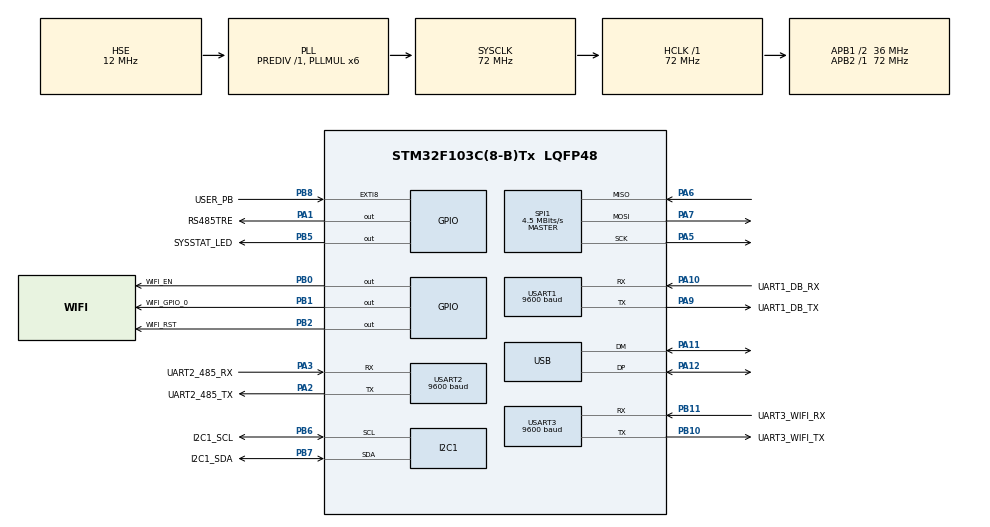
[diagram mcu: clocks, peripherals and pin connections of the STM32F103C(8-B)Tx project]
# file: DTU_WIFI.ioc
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Dma.Request0=USART1_TX
Dma.Request1=USART1_RX
Dma.Request2=USART2_TX
Dma.Request3=USART2_RX
Dma.Request4=USART3_TX
Dma.Request5=USART3_RX
Dma.USART1_RX.1.Direction=DMA_PERIPH_TO_MEMORY
Dma.USART1_RX.1.Instance=DMA1_Channel5
Dma.USART1_RX.1.MemDataAlignment=DMA_MDATAALIGN_BYTE
Dma.USART1_RX.1.MemInc=DMA_MINC_ENABLE
Dma.USART1_RX.1.Mode=DMA_CIRCULAR
Dma.USART1_RX.1.PeriphDataAlignment=DMA_PDATAALIGN_BYTE
Dma.USART1_RX.1.PeriphInc=DMA_PINC_DISABLE
Dma.USART1_RX.1.Priority=DMA_PRIORITY_LOW
Dma.USART1_TX.0.Direction=DMA_MEMORY_TO_PERIPH
Dma.USART1_TX.0.Instance=DMA1_Channel4
Dma.USART1_TX.0.MemDataAlignment=DMA_MDATAALIGN_BYTE
Dma.USART1_TX.0.MemInc=DMA_MINC_ENABLE
Dma.USART1_TX.0.Mode=DMA_CIRCULAR
Dma.USART1_TX.0.PeriphDataAlignment=DMA_PDATAALIGN_BYTE
Dma.USART1_TX.0.PeriphInc=DMA_PINC_DISABLE
Dma.USART1_TX.0.Priority=DMA_PRIORITY_LOW
Dma.USART2_RX.3.Direction=DMA_PERIPH_TO_MEMORY
Dma.USART2_RX.3.Instance=DMA1_Channel6
Dma.USART2_RX.3.MemDataAlignment=DMA_MDATAALIGN_BYTE
Dma.USART2_RX.3.MemInc=DMA_MINC_ENABLE
Dma.USART2_RX.3.Mode=DMA_CIRCULAR
Dma.USART2_RX.3.PeriphDataAlignment=DMA_PDATAALIGN_BYTE
Dma.USART2_RX.3.PeriphInc=DMA_PINC_DISABLE
Dma.USART2_RX.3.Priority=DMA_PRIORITY_LOW
Dma.USART2_TX.2.Direction=DMA_MEMORY_TO_PERIPH
Dma.USART2_TX.2.Instance=DMA1_Channel7
Dma.USART2_TX.2.MemDataAlignment=DMA_MDATAALIGN_BYTE
Dma.USART2_TX.2.MemInc=DMA_MINC_ENABLE
Dma.USART2_TX.2.Mode=DMA_CIRCULAR
Dma.USART2_TX.2.PeriphDataAlignment=DMA_PDATAALIGN_BYTE
Dma.USART2_TX.2.PeriphInc=DMA_PINC_DISABLE
Dma.USART2_TX.2.Priority=DMA_PRIORITY_LOW
Dma.USART3_RX.5.Direction=DMA_PERIPH_TO_MEMORY
Dma.USART3_RX.5.Instance=DMA1_Channel3
Dma.USART3_RX.5.MemDataAlignment=DMA_MDATAALIGN_BYTE
Dma.USART3_RX.5.MemInc=DMA_MINC_ENABLE
Dma.USART3_RX.5.Mode=DMA_CIRCULAR
Dma.USART3_RX.5.PeriphDataAlignment=DMA_PDATAALIGN_BYTE
Dma.USART3_RX.5.PeriphInc=DMA_PINC_DISABLE
Dma.USART3_RX.5.Priority=DMA_PRIORITY_LOW
Dma.USART3_TX.4.Direction=DMA_MEMORY_TO_PERIPH
Dma.USART3_TX.4.Instance=DMA1_Channel2
Dma.USART3_TX.4.MemDataAlignment=DMA_MDATAALIGN_BYTE
Dma.USART3_TX.4.MemInc=DMA_MINC_ENABLE
Dma.USART3_TX.4.Mode=DMA_CIRCULAR
Dma.USART3_TX.4.PeriphDataAlignment=DMA_PDATAALIGN_BYTE
Dma.USART3_TX.4.PeriphInc=DMA_PINC_DISABLE
Dma.USART3_TX.4.Priority=DMA_PRIORITY_LOW
IWDG.Prescaler=IWDG_PRESCALER_64
Mcu.Family=STM32F1
Mcu.Name=STM32F103C(8-B)Tx
Mcu.Package=LQFP48
NVIC.DMA1_Channel2_IRQn=true\:0\:0\:false\:true\:true\:1\:false
NVIC.DMA1_Channel3_IRQn=true\:0\:0\:false\:true\:true\:2\:false
NVIC.DMA1_Channel4_IRQn=true\:0\:0\:false\:true\:true\:3\:false
NVIC.DMA1_Channel5_IRQn=true\:0\:0\:false\:true\:true\:4\:false
NVIC.DMA1_Channel6_IRQn=true\:0\:0\:false\:true\:true\:5\:false
NVIC.DMA1_Channel7_IRQn=true\:0\:0\:false\:true\:true\:6\:false
NVIC.EXTI9_5_IRQn=true\:0\:0\:false\:true\:true\:8\:true
NVIC.I2C1_ER_IRQn=true\:0\:0\:false\:true\:true\:13\:true
NVIC.I2C1_EV_IRQn=true\:0\:0\:false\:true\:true\:12\:true
NVIC.PriorityGroup=NVIC_PRIORITYGROUP_4
NVIC.RTC_IRQn=true\:0\:0\:false\:true\:true\:15\:true
NVIC.SPI1_IRQn=true\:0\:0\:false\:true\:true\:14\:true
NVIC.TIM4_IRQn=true\:0\:0\:false\:true\:true\:7\:true
NVIC.USART1_IRQn=true\:0\:0\:false\:true\:true\:9\:true
NVIC.USART2_IRQn=true\:0\:0\:false\:true\:true\:10\:true
NVIC.USART3_IRQn=true\:0\:0\:false\:true\:true\:11\:true
PA0-WKUP.Mode=SYS_WakeUp0
PA0-WKUP.Signal=SYS_WKUP
PA1.GPIO_Label=RS485TRE
PA1.Signal=GPIO_Output
PA10.GPIO_Label=UART1_DB_RX
PA10.Mode=Asynchronous
PA10.Signal=USART1_RX
PA11.Mode=Device
PA11.Signal=USB_DM
PA12.Mode=Device
PA12.Signal=USB_DP
PA13.GPIO_Label=SYS_SWDIO
PA13.Signal=SYS_JTMS-SWDIO
PA14.GPIO_Label=SYS_SWCLK
PA14.Signal=SYS_JTCK-SWCLK
PA2.GPIO_Label=UART2_485_TX
PA2.Mode=Asynchronous
PA2.Signal=USART2_TX
PA3.GPIO_Label=UART2_485_RX
PA3.Mode=Asynchronous
PA3.Signal=USART2_RX
PA4.GPIO_Label=SPI1NSS
PA4.Signal=SPI1_NSS
PA5.Mode=Full_Duplex_Master
PA5.Signal=SPI1_SCK
PA6.Mode=Full_Duplex_Master
PA6.Signal=SPI1_MISO
PA7.Mode=Full_Duplex_Master
PA7.Signal=SPI1_MOSI
PA9.GPIO_Label=UART1_DB_TX
PA9.Mode=Asynchronous
PA9.Signal=USART1_TX
PB0.GPIO_Label=WIFI_EN
PB0.Signal=GPIO_Output
PB1.GPIO_Label=WIFI_GPIO_0
PB1.Signal=GPIO_Output
PB10.GPIO_Label=UART3_WIFI_TX
PB10.Mode=Asynchronous
PB10.Signal=USART3_TX
PB11.GPIO_Label=UART3_WIFI_RX
PB11.Mode=Asynchronous
PB11.Signal=USART3_RX
PB2.GPIO_Label=WIFI_RST
PB2.Signal=GPIO_Output
PB5.GPIO_Label=SYSSTAT_LED
PB5.Signal=GPIO_Output
PB6.GPIO_Label=I2C1_SCL
PB6.Mode=I2C
PB6.Signal=I2C1_SCL
PB7.GPIO_Label=I2C1_SDA
PB7.Mode=I2C
PB7.Signal=I2C1_SDA
PB8.GPIO_Label=USER_PB
PB8.GPIO_ModeDefaultEXTI=GPIO_MODE_IT_FALLING
PB8.GPIO_PuPd=GPIO_PULLUP
PB8.Signal=GPXTI8
PD0-OSC_IN.Mode=HSE-External-Oscillator
PD0-OSC_IN.Signal=RCC_OSC_IN
PD1-OSC_OUT.Mode=HSE-External-Oscillator
PD1-OSC_OUT.Signal=RCC_OSC_OUT
ProjectManager.HeapSize=0x200
ProjectManager.StackSize=0x400
ProjectManager.TargetToolchain=SW4STM32
RCC.AHBFreq_Value=72000000
RCC.APB1CLKDivider=RCC_HCLK_DIV2
RCC.APB1Freq_Value=36000000
RCC.APB1TimFreq_Value=72000000
RCC.APB2Freq_Value=72000000
RCC.APB2TimFreq_Value=72000000
RCC.HCLKFreq_Value=72000000
RCC.HSE_VALUE=12000000
RCC.PLLMUL=RCC_PLL_MUL6
RCC.PLLSourceVirtual=RCC_PLLSOURCE_HSE
RCC.SYSCLKFreq_VALUE=72000000
RCC.SYSCLKSource=RCC_SYSCLKSOURCE_PLLCLK
RCC.USBFreq_Value=48000000
RCC.USBPrescaler=RCC_USBCLKSOURCE_PLL_DIV1_5
RTC.Date=19
RTC.Month=RTC_MONTH_APRIL
RTC.WeekDay=RTC_WEEKDAY_THURSDAY
RTC.Year=18
SPI1.BaudRatePrescaler=SPI_BAUDRATEPRESCALER_16
SPI1.CalculateBaudRate=4.5 MBits/s
SPI1.Direction=SPI_DIRECTION_2LINES
SPI1.Mode=SPI_MODE_MASTER
SPI1.VirtualType=VM_MASTER
TIM4.Period=9999
TIM4.Prescaler=7199
USART1.BaudRate=9600
USART1.VirtualMode=VM_ASYNC
USART2.BaudRate=9600
USART2.VirtualMode=VM_ASYNC
USART3.BaudRate=9600
USART3.VirtualMode=VM_ASYNC
VP_IWDG_VS_IWDG.Mode=IWDG_Activate
VP_RTC_VS_RTC_Activate.Mode=RTC_Enabled
VP_RTC_VS_RTC_Calendar.Mode=RTC_Calendar
VP_SYS_VS_ND.Mode=No_Debug
VP_TIM4_VS_ClockSourceINT.Mode=Internal
board=OPBOARD_WIFI

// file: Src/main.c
/**
  ******************************************************************************
  * @file           : main.c
  * @brief          : Main program body
  ******************************************************************************
  ** This notice applies to any and all portions of this file
  * that are not between comment pairs USER CODE BEGIN and
  * USER CODE END. Other portions of this file, whether
  * inserted by the user or by software development tools
  * are owned by their respective copyright owners.
  *
  * COPYRIGHT(c) 2018 STMicroelectronics
  *
  * Redistribution and use in source and binary forms, with or without modification,
  * are permitted provided that the following conditions are met:
  *   1. Redistributions of source code must retain the above copyright notice,
  *      this list of conditions and the following disclaimer.
  *   2. Redistributions in binary form must reproduce the above copyright notice,
  *      this list of conditions and the following disclaimer in the documentation
  *      and/or other materials provided with the distribution.
  *   3. Neither the name of STMicroelectronics nor the names of its contributors
  *      may be used to endorse or promote products derived from this software
  *      without specific prior written permission.
  *
  * THIS SOFTWARE IS PROVIDED BY THE COPYRIGHT HOLDERS AND CONTRIBUTORS "AS IS"
  * AND ANY EXPRESS OR IMPLIED WARRANTIES, INCLUDING, BUT NOT LIMITED TO, THE
  * IMPLIED WARRANTIES OF MERCHANTABILITY AND FITNESS FOR A PARTICULAR PURPOSE ARE
  * DISCLAIMED. IN NO EVENT SHALL THE COPYRIGHT HOLDER OR CONTRIBUTORS BE LIABLE
  * FOR ANY DIRECT, INDIRECT, INCIDENTAL, SPECIAL, EXEMPLARY, OR CONSEQUENTIAL
  * DAMAGES (INCLUDING, BUT NOT LIMITED TO, PROCUREMENT OF SUBSTITUTE GOODS OR
  * SERVICES; LOSS OF USE, DATA, OR PROFITS; OR BUSINESS INTERRUPTION) HOWEVER
  * CAUSED AND ON ANY THEORY OF LIABILITY, WHETHER IN CONTRACT, STRICT LIABILITY,
  * OR TORT (INCLUDING NEGLIGENCE OR OTHERWISE) ARISING IN ANY WAY OUT OF THE USE
  * OF THIS SOFTWARE, EVEN IF ADVISED OF THE POSSIBILITY OF SUCH DAMAGE.
  *
  ******************************************************************************
  */
#include "main.h"
#include "stm32f1xx_hal.h"
#include "dma.h"
#include "i2c.h"
#include "iwdg.h"
#include "rtc.h"
#include "spi.h"
#include "tim.h"
#include "usart.h"
#include "usb.h"
#include "gpio.h"

/* USER CODE BEGIN PV */
/* Private variables ---------------------------------------------------------*/

/* USER CODE END PV */

void SystemClock_Config(void);

static void MX_NVIC_Init(void);

/* USER CODE BEGIN PFP */
/* Private function prototypes -----------------------------------------------*/
void info_display(void);

/* USER CODE END PFP */

int main(void) {

    /* MCU Configuration----------------------------------------------------------*/

    /* Reset of all peripherals, Initializes the Flash interface and the Systick. */
    HAL_Init();

    /* Configure the system clock */
    SystemClock_Config();

    /* Initialize all configured peripherals */
    MX_GPIO_Init();
    MX_DMA_Init();
    MX_USART2_UART_Init();
    MX_USART3_UART_Init();
    MX_USART1_UART_Init();
    MX_SPI1_Init();
    MX_I2C1_Init();
    MX_RTC_Init();
    MX_TIM4_Init();
//    MX_IWDG_Init();
    MX_USB_PCD_Init();

    /* Initialize interrupts */
    MX_NVIC_Init();
    /* USER CODE BEGIN 2 */
    info_display();
    /* USER CODE END 2 */

    /* Infinite loop */
    /* USER CODE BEGIN WHILE */
    while (1) {

        HAL_Delay(1000);
        HAL_GPIO_TogglePin(SYSSTAT_LED_GPIO_Port, SYSSTAT_LED_Pin);

        /* USER CODE END WHILE */

    }

}

void SystemClock_Config(void) {

    RCC_OscInitTypeDef RCC_OscInitStruct;
    RCC_ClkInitTypeDef RCC_ClkInitStruct;
    RCC_PeriphCLKInitTypeDef PeriphClkInit;

    /**Initializes the CPU, AHB and APB busses clocks
    */
    RCC_OscInitStruct.OscillatorType = RCC_OSCILLATORTYPE_LSI | RCC_OSCILLATORTYPE_HSE;
    RCC_OscInitStruct.HSEState = RCC_HSE_ON;
    RCC_OscInitStruct.HSEPredivValue = RCC_HSE_PREDIV_DIV1;
    RCC_OscInitStruct.HSIState = RCC_HSI_ON;
    RCC_OscInitStruct.LSIState = RCC_LSI_ON;
    RCC_OscInitStruct.PLL.PLLState = RCC_PLL_ON;
    RCC_OscInitStruct.PLL.PLLSource = RCC_PLLSOURCE_HSE;
    RCC_OscInitStruct.PLL.PLLMUL = RCC_PLL_MUL6;
    if (HAL_RCC_OscConfig(&RCC_OscInitStruct) != HAL_OK) {
        _Error_Handler(__FILE__, __LINE__);
    }

    /**Initializes the CPU, AHB and APB busses clocks
    */
    RCC_ClkInitStruct.ClockType = RCC_CLOCKTYPE_HCLK | RCC_CLOCKTYPE_SYSCLK
                                  | RCC_CLOCKTYPE_PCLK1 | RCC_CLOCKTYPE_PCLK2;
    RCC_ClkInitStruct.SYSCLKSource = RCC_SYSCLKSOURCE_PLLCLK;
    RCC_ClkInitStruct.AHBCLKDivider = RCC_SYSCLK_DIV1;
    RCC_ClkInitStruct.APB1CLKDivider = RCC_HCLK_DIV2;
    RCC_ClkInitStruct.APB2CLKDivider = RCC_HCLK_DIV1;

    if (HAL_RCC_ClockConfig(&RCC_ClkInitStruct, FLASH_LATENCY_2) != HAL_OK) {
        _Error_Handler(__FILE__, __LINE__);
    }

    PeriphClkInit.PeriphClockSelection = RCC_PERIPHCLK_RTC | RCC_PERIPHCLK_USB;
    PeriphClkInit.RTCClockSelection = RCC_RTCCLKSOURCE_LSI;
    PeriphClkInit.UsbClockSelection = RCC_USBCLKSOURCE_PLL_DIV1_5;
    if (HAL_RCCEx_PeriphCLKConfig(&PeriphClkInit) != HAL_OK) {
        _Error_Handler(__FILE__, __LINE__);
    }

    /**Configure the Systick interrupt time
    */
    HAL_SYSTICK_Config(HAL_RCC_GetHCLKFreq() / 1000);

    /**Configure the Systick
    */
    HAL_SYSTICK_CLKSourceConfig(SYSTICK_CLKSOURCE_HCLK);

    /* SysTick_IRQn interrupt configuration */
    HAL_NVIC_SetPriority(SysTick_IRQn, 0, 0);
}

/**
  * @brief NVIC Configuration.
  * @retval None
  */
static void MX_NVIC_Init(void) {
    /* DMA1_Channel2_IRQn interrupt configuration */
    HAL_NVIC_SetPriority(DMA1_Channel2_IRQn, 0, 0);
    HAL_NVIC_EnableIRQ(DMA1_Channel2_IRQn);
    /* DMA1_Channel3_IRQn interrupt configuration */
    HAL_NVIC_SetPriority(DMA1_Channel3_IRQn, 0, 0);
    HAL_NVIC_EnableIRQ(DMA1_Channel3_IRQn);
    /* DMA1_Channel4_IRQn interrupt configuration */
    HAL_NVIC_SetPriority(DMA1_Channel4_IRQn, 0, 0);
    HAL_NVIC_EnableIRQ(DMA1_Channel4_IRQn);
    /* DMA1_Channel5_IRQn interrupt configuration */
    HAL_NVIC_SetPriority(DMA1_Channel5_IRQn, 0, 0);
    HAL_NVIC_EnableIRQ(DMA1_Channel5_IRQn);
    /* DMA1_Channel6_IRQn interrupt configuration */
    HAL_NVIC_SetPriority(DMA1_Channel6_IRQn, 0, 0);
    HAL_NVIC_EnableIRQ(DMA1_Channel6_IRQn);
    /* DMA1_Channel7_IRQn interrupt configuration */
    HAL_NVIC_SetPriority(DMA1_Channel7_IRQn, 0, 0);
    HAL_NVIC_EnableIRQ(DMA1_Channel7_IRQn);
    /* TIM4_IRQn interrupt configuration */
    HAL_NVIC_SetPriority(TIM4_IRQn, 0, 0);
    HAL_NVIC_EnableIRQ(TIM4_IRQn);
    /* EXTI9_5_IRQn interrupt configuration */
    HAL_NVIC_SetPriority(EXTI9_5_IRQn, 0, 0);
    HAL_NVIC_EnableIRQ(EXTI9_5_IRQn);
    /* USART1_IRQn interrupt configuration */
    HAL_NVIC_SetPriority(USART1_IRQn, 0, 0);
    HAL_NVIC_EnableIRQ(USART1_IRQn);
    /* USART2_IRQn interrupt configuration */
    HAL_NVIC_SetPriority(USART2_IRQn, 0, 0);
    HAL_NVIC_EnableIRQ(USART2_IRQn);
    /* USART3_IRQn interrupt configuration */
    HAL_NVIC_SetPriority(USART3_IRQn, 0, 0);
    HAL_NVIC_EnableIRQ(USART3_IRQn);
    /* I2C1_EV_IRQn interrupt configuration */
    HAL_NVIC_SetPriority(I2C1_EV_IRQn, 0, 0);
    HAL_NVIC_EnableIRQ(I2C1_EV_IRQn);
    /* I2C1_ER_IRQn interrupt configuration */
    HAL_NVIC_SetPriority(I2C1_ER_IRQn, 0, 0);
    HAL_NVIC_EnableIRQ(I2C1_ER_IRQn);
    /* SPI1_IRQn interrupt configuration */
    HAL_NVIC_SetPriority(SPI1_IRQn, 0, 0);
    HAL_NVIC_EnableIRQ(SPI1_IRQn);
    /* RTC_IRQn interrupt configuration */
    HAL_NVIC_SetPriority(RTC_IRQn, 0, 0);
    HAL_NVIC_EnableIRQ(RTC_IRQn);
}

void _Error_Handler(char *file, int line) {
    while (1) {
    }
}

/************************ (C) COPYRIGHT STMicroelectronics *****END OF FILE****/
